# max32572 register map
Vendor: Maxim-Integrated; Series: ARMCM4; File version: 1.0
CPU: CM4 r2p1, little endian, MPU, FPU, 3 interrupt priority bits
Registers are 32-bit, read-write, reset 0x0 unless marked. A register's access mark holds for its fields unless they carry their own. Offsets are from the block's base; [hi:lo] are bit positions.

## SPIXFC_FIFO — SPI XiP Master Controller FIFO.
Base 0x400BC000
0x00 TX_8 8-bit — SPI TX FIFO 8-Bit Write
0x00 TX_16 16-bit (alternate view of TX_8) — SPI TX FIFO 16-Bit Write
0x00 TX_32 (alternate view of TX_8) — SPI TX FIFO 32-Bit Write
0x04 RX_8 8-bit — SPI RX FIFO 8-Bit Access
0x04 RX_16 16-bit (alternate view of RX_8) — SPI RX FIFO 16-Bit Access
0x04 RX_32 (alternate view of RX_8) — SPI RX FIFO 32-Bit Access

## TMR0 — 32-bit reloadable timer that can be used for timing and event counting.
Base 0x40010000
Same registers: TMR1 0x40011000, TMR2 0x40012000, TMR3 0x40013000, TMR4 0x40014000, TMR5 0x40015000
0x00 CNT reset 0x1 — Count. This register stores the current timer count.
  [31:0] COUNT
0x04 CMP reset 0xFFFF — Compare. This register stores the compare value, which is used to set the maximum count value to initiate a reload of the timer to 0x0001.
  [31:0] COMPARE
0x08 PWM — PWM. This register stores the value that is compared to the current timer count.
0x0C INTFL write-1-clears — Clear Interrupt. Writing a value (0 or 1) to a bit in this register clears the associated interrupt.
  [0] IRQ — Clear Interrupt.
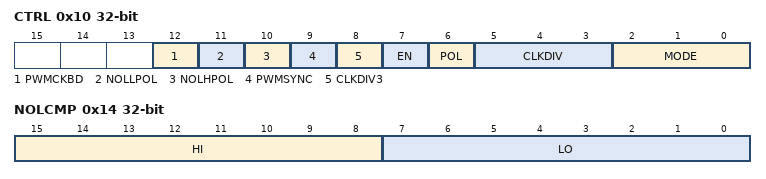
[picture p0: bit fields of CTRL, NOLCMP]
0x10 CTRL — Timer Control Register.
  [12] PWMCKBD — Timer PWM output 0A Mode Disable.
    1=dis (Disable.); 0=en (Enable.)
  [11] NOLLPOL — Timer PWM output 0A' polarity bit.
    0=dis (Disable.); 1=en (Enable.)
  [10] NOLHPOL — Timer PWM output 0A polarity bit.
    0=dis (Disable.); 1=en (Enable.)
  [9] PWMSYNC — Timer PWM Synchronization Mode Enable.
    0=dis (Disable.); 1=en (Enable.)
  [8] CLKDIV3 — MSB of prescaler value.
  [7] EN — Timer Enable.
    0=dis (Disable.); 1=en (Enable.)
  [6] POL — Timer input/output polarity bit.
    0=Active High; 1=Active Low
  [5:3] CLKDIV — Prescaler. Set the Timer's prescaler value. The prescaler divides the PCLK input to the timer and sets the Timer's Count Clock, F_CNT_CLK = PCLK (HZ) /prescaler. The Timer's prescaler setting is a 4-bit value with pres3:pres[2:0].
    0=div1 (Divide by 1.); 1=div2 (Divide by 2.); 2=div4 (Divide by 4.); 3=div8 (Divide by 8.); 4=div16 (Divide by 16.); 5=div32 (Divide by 32.); 6=div64 (Divide by 64.); 7=div128 (Divide by 128.)
  [2:0] MODE — Timer Mode.
    0=One Shot Mode; 1=Continuous Mode; 2=Counter Mode; 3=pwm (PWM Mode.); 4=Capture Mode; 5=Compare Mode; 6=Gated Mode; 7=Capture/Compare Mode
0x14 NOLCMP — Timer Non-Overlapping Compare Register.
  [15:8] HI — Non-overlapping High Compare. The 8-bit timer count value of non-overlapping time between falling edge of PWM output 0A' and next rising edge of PWM output 0A.
  [7:0] LO — Non-overlapping Low Compare. The 8-bit timer count value of non-overlapping time between falling edge of PWM output 0A and next rising edge of PWM output 0A'.

## TRNG — Random Number Generator.
Base 0x4004D000
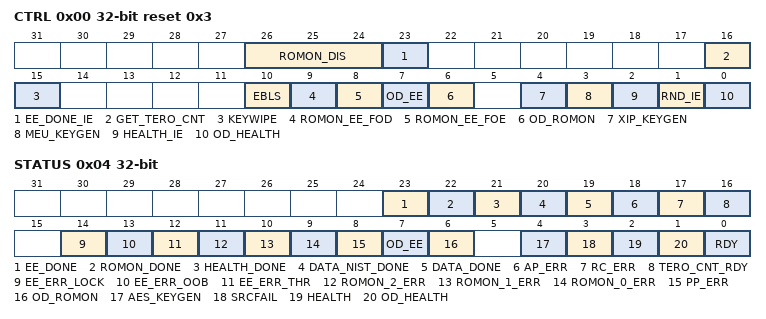
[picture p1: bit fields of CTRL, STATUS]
0x00 CTRL reset 0x3 — TRNG Control Register.
  [26:24] ROMON_DIS — Ring Oscillator Disable.
    1=RO_0 (Ring Oscillator 0.); 2=RO_1 (Ring Oscillator 1.); 4=RO_2 (Ring Oscillator 2.)
  [23] EE_DONE_IE — Entropy Estimator Done Interrupt Enable.
  [16] GET_TERO_CNT — Get Tero Count.
  [15] KEYWIPE — To wipe the Battery Backed key.
  [10] EBLS — Entropy Bit Load Select.
  [9] ROMON_EE_FOD — Ring Oscillator Monitors and Entropy Estimator Freeze on Done.
  [8] ROMON_EE_FOE — Ring Oscillator Monitors and Entropy Estimator Freeze on Error.
  [7] OD_EE — Start entropy estimator on demand test.
  [6] OD_ROMON — Start ring oscillator monitor on demand test.
  [4] XIP_KEYGEN — If set to 1, the TRNG generates the 128-bit QSPI (XIP) keys.
  [3] MEU_KEYGEN — If set to 1, the TRNG generates the 256-bit AES MEU keys.
  [2] HEALTH_IE — Enable IRQ generation when a health test fails.
  [1] RND_IE — To enable IRQ generation when a new 32-bit Random number is ready.
    0=disable; 1=enable
  [0] OD_HEALTH — Start On-Demand health test.
0x04 STATUS — Data. The content of this register is valid only when RNG_IS = 1. When TRNG is disabled, read returns 0x0000 0000.
  [23] EE_DONE — Entropy Estimator Test Done.
  [22] ROMON_DONE — Ring Oscillator Monitor Test Done.
  [21] HEALTH_DONE — Health Test Done.
  [20] DATA_NIST_DONE — Data NIST register has been loaded with at least 32 new entropy bits.
  [19] DATA_DONE — Data register has been loaded with at least 32 new entropy bits.
  [18] AP_ERR — Adaptive Proportion Error.
  [17] RC_ERR — Repetition Count Error.
  [16] TERO_CNT_RDY — TERO Count Ready.
  [14] EE_ERR_LOCK — Entropy Estimator Lock Error.
  [13] EE_ERR_OOB — Entropy Estimator Out of Bounds Error..
  [12] EE_ERR_THR — Entropy Estimator Threshold Error.
  [11] ROMON_2_ERR — Ring Oscillator 2 Monitor Error.
  [10] ROMON_1_ERR — Ring Oscillator 1 Monitor Error.
  [9] ROMON_0_ERR — Ring Oscillator 0 Monitor Error.
  [8] PP_ERR — Post process error.
  [7] OD_EE — On demand entropy estimator status.
  [6] OD_ROMON — On demand ring oscillator test status.
  [4] AES_KEYGEN — AESKGD.
  [3] SRCFAIL — Entropy source has failed.
  [2] HEALTH — Health test status.
  [1] OD_HEALTH — On-Demand health test status.
  [0] RDY — 32-bit random data is ready to read from TRNG_DATA register. Reading TRNG_DATA when RND_RDY=0 will return all 0's. IRQ is generated when RND_RDY=1 if TRNG_CN.RND_IRQ_EN=1.
    0=Busy (TRNG Busy); 1=Ready (32 bit random data is ready)
0x08 DATA ro — Data. The content of this register is valid only when RNG_IS = 1. When TRNG is disabled, read returns 0x0000 0000.
  [31:0] DATA — Data. The content of this register is valid only when RNG_IS =1. When TNRG is disabled, read returns 0x0000 0000.
0x38 DATA_NIST
  [31:0] DATA — Ring Oscillator 1 Monitor Last Ring Oscillator Count.
